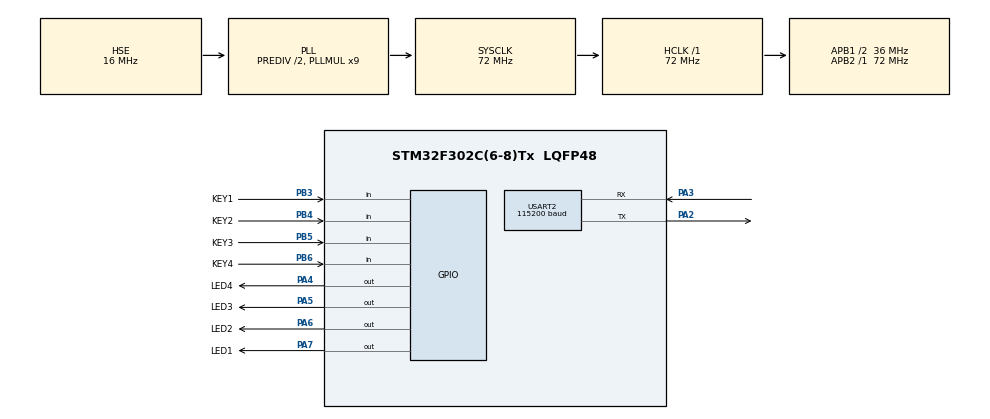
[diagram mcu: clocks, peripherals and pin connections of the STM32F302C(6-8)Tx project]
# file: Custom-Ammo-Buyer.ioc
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Mcu.Family=STM32F3
Mcu.Name=STM32F302C(6-8)Tx
Mcu.Package=LQFP48
NVIC.PriorityGroup=NVIC_PRIORITYGROUP_4
NVIC.TIM6_DAC_IRQn=true\:0\:0\:false\:false\:true\:true\:true\:true
NVIC.USART2_IRQn=true\:0\:0\:false\:false\:true\:true\:true\:true
PA13.Mode=Serial_Wire
PA13.Signal=SYS_JTMS-SWDIO
PA14.Mode=Serial_Wire
PA14.Signal=SYS_JTCK-SWCLK
PA2.Mode=Asynchronous
PA2.Signal=USART2_TX
PA3.Mode=Asynchronous
PA3.Signal=USART2_RX
PA4.GPIO_Label=LED4
PA4.Signal=GPIO_Output
PA5.GPIO_Label=LED3
PA5.Signal=GPIO_Output
PA6.GPIO_Label=LED2
PA6.Signal=GPIO_Output
PA7.GPIO_Label=LED1
PA7.Signal=GPIO_Output
PB3.GPIO_Label=KEY1
PB3.Signal=GPIO_Input
PB4.GPIO_Label=KEY2
PB4.Signal=GPIO_Input
PB5.GPIO_Label=KEY3
PB5.Signal=GPIO_Input
PB6.GPIO_Label=KEY4
PB6.Signal=GPIO_Input
PF0-OSC_IN.Mode=HSE-External-Oscillator
PF0-OSC_IN.Signal=RCC_OSC_IN
PF1-OSC_OUT.Mode=HSE-External-Oscillator
PF1-OSC_OUT.Signal=RCC_OSC_OUT
ProjectManager.HeapSize=0x200
ProjectManager.StackSize=0x400
ProjectManager.TargetToolchain=MDK-ARM V5.32
RCC.AHBFreq_Value=72000000
RCC.APB1CLKDivider=RCC_HCLK_DIV2
RCC.APB1Freq_Value=36000000
RCC.APB1TimFreq_Value=72000000
RCC.APB2Freq_Value=72000000
RCC.APB2TimFreq_Value=72000000
RCC.CortexFreq_Value=72000000
RCC.HCLKFreq_Value=72000000
RCC.HSE_VALUE=16000000
RCC.HSI_VALUE=8000000
RCC.LSE_VALUE=32768
RCC.PLLMUL=RCC_PLL_MUL9
RCC.PLLSourceVirtual=RCC_PLLSOURCE_HSE
RCC.RCC_PLLsource_Clock_Source_FROM_HSE=RCC_HSE_PREDIV_DIV2
RCC.SYSCLKFreq_VALUE=72000000
RCC.SYSCLKSourceVirtual=RCC_SYSCLKSOURCE_PLLCLK
RCC.USBFreq_Value=72000000
TIM6.Period=1000-1
TIM6.Prescaler=80-1
USART2.BaudRate=115200
USART2.Mode=MODE_TX
USART2.VirtualMode-Asynchronous=VM_ASYNC
VP_TIM6_VS_ClockSourceINT.Mode=Enable_Timer
board=custom

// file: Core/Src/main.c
/* USER CODE BEGIN Header */
/**
  ******************************************************************************
  * @file           : main.c
  * @brief          : Main program body
  ******************************************************************************
  * @attention
  *
  * Copyright (c) 2025 STMicroelectronics.
  * All rights reserved.
  *
  * This software is licensed under terms that can be found in the LICENSE file
  * in the root directory of this software component.
  * If no LICENSE file comes with this software, it is provided AS-IS.
  *
  ******************************************************************************
  */
/* USER CODE END Header */
#include "main.h"
#include "tim.h"
#include "usart.h"
#include "gpio.h"

void SystemClock_Config(void);

int main(void)
{

  /* MCU Configuration--------------------------------------------------------*/

  /* Reset of all peripherals, Initializes the Flash interface and the Systick. */
  HAL_Init();

  /* Configure the system clock */
  SystemClock_Config();

  /* Initialize all configured peripherals */
  MX_GPIO_Init();
  MX_TIM6_Init();
  MX_USART2_UART_Init();
  /* USER CODE BEGIN 2 */
  HAL_TIM_Base_Start_IT(&htim6);

  /* USER CODE END 2 */

  /* Infinite loop */
  /* USER CODE BEGIN WHILE */
  while (1)
  {
    // state[1] = HAL_GPIO_ReadPin(KEY1_GPIO_Port, KEY1_Pin);
    // pdata[0] = (uint8_t)state[1];
    // if (state[1] == GPIO_PIN_SET) {
    //   HAL_GPIO_WritePin(LED1_GPIO_Port, LED1_Pin, GPIO_PIN_SET);
    // }else {
    //   HAL_GPIO_WritePin(LED1_GPIO_Port, LED1_Pin, GPIO_PIN_RESET);
    // }
    //
    // state[2] = HAL_GPIO_ReadPin(KEY2_GPIO_Port, KEY2_Pin);
    // pdata[1] = (uint8_t)state[2];
    // if (state[2] == GPIO_PIN_SET) {
    //   HAL_GPIO_WritePin(LED2_GPIO_Port, LED2_Pin, GPIO_PIN_SET);
    // }else {
    //   HAL_GPIO_WritePin(LED2_GPIO_Port, LED2_Pin, GPIO_PIN_RESET);
    // }
    //
    // state[3] = HAL_GPIO_ReadPin(KEY3_GPIO_Port, KEY3_Pin);
    // pdata[2] = (uint8_t)state[3];
    // if (state[3] == GPIO_PIN_SET) {
    //   HAL_GPIO_WritePin(LED3_GPIO_Port, LED3_Pin, GPIO_PIN_SET);
    // }else {
    //   HAL_GPIO_WritePin(LED3_GPIO_Port, LED3_Pin, GPIO_PIN_RESET);
    // }

    /* USER CODE END WHILE */

  }
}

void SystemClock_Config(void)
{
  RCC_OscInitTypeDef RCC_OscInitStruct = {0};
  RCC_ClkInitTypeDef RCC_ClkInitStruct = {0};

  /** Initializes the RCC Oscillators according to the specified parameters
  * in the RCC_OscInitTypeDef structure.
  */
  RCC_OscInitStruct.OscillatorType = RCC_OSCILLATORTYPE_HSE;
  RCC_OscInitStruct.HSEState = RCC_HSE_ON;
  RCC_OscInitStruct.HSEPredivValue = RCC_HSE_PREDIV_DIV2;
  RCC_OscInitStruct.HSIState = RCC_HSI_ON;
  RCC_OscInitStruct.PLL.PLLState = RCC_PLL_ON;
  RCC_OscInitStruct.PLL.PLLSource = RCC_PLLSOURCE_HSE;
  RCC_OscInitStruct.PLL.PLLMUL = RCC_PLL_MUL9;
  if (HAL_RCC_OscConfig(&RCC_OscInitStruct) != HAL_OK)
  {
    Error_Handler();
  }

  /** Initializes the CPU, AHB and APB buses clocks
  */
  RCC_ClkInitStruct.ClockType = RCC_CLOCKTYPE_HCLK|RCC_CLOCKTYPE_SYSCLK
                              |RCC_CLOCKTYPE_PCLK1|RCC_CLOCKTYPE_PCLK2;
  RCC_ClkInitStruct.SYSCLKSource = RCC_SYSCLKSOURCE_PLLCLK;
  RCC_ClkInitStruct.AHBCLKDivider = RCC_SYSCLK_DIV1;
  RCC_ClkInitStruct.APB1CLKDivider = RCC_HCLK_DIV2;
  RCC_ClkInitStruct.APB2CLKDivider = RCC_HCLK_DIV1;

  if (HAL_RCC_ClockConfig(&RCC_ClkInitStruct, FLASH_LATENCY_2) != HAL_OK)
  {
    Error_Handler();
  }
}

void Error_Handler(void)
{
  __disable_irq();
  while (1)
  {
  }
}
